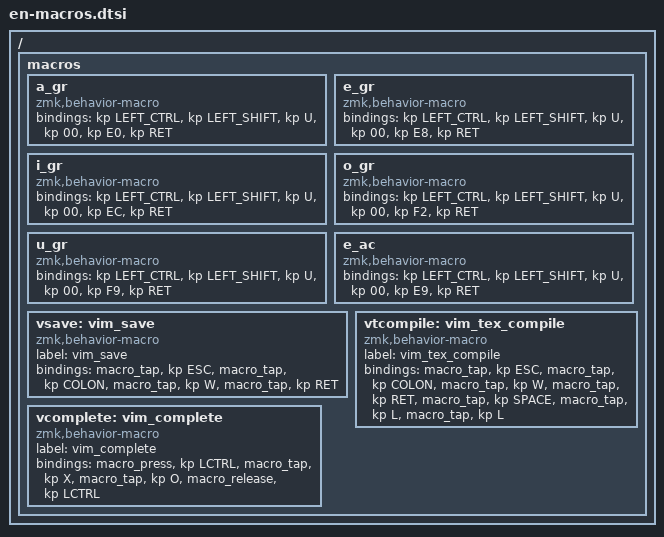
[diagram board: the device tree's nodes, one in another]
/ {

    macros {
        
      // Character à
      a_gr: a_gr {
          compatible = "zmk,behavior-macro";
          #binding-cells = <0>;
          bindings = <&kp LEFT_CTRL>, <&kp LEFT_SHIFT>, <&kp U>, <&kp 00>, <&kp E0>, <&kp RET>;
      };
        
      // Character è
      e_gr: e_gr {
          compatible = "zmk,behavior-macro";
          #binding-cells = <0>;
          bindings = <&kp LEFT_CTRL>, <&kp LEFT_SHIFT>, <&kp U>, <&kp 00>, <&kp E8>, <&kp RET>;
      };
        
      // Character ì
      i_gr: i_gr {
          compatible = "zmk,behavior-macro";
          #binding-cells = <0>;
          bindings = <&kp LEFT_CTRL>, <&kp LEFT_SHIFT>, <&kp U>, <&kp 00>, <&kp EC>, <&kp RET>;
      };
        
      // Character ò
      o_gr: o_gr {
          compatible = "zmk,behavior-macro";
          #binding-cells = <0>;
          bindings = <&kp LEFT_CTRL>, <&kp LEFT_SHIFT>, <&kp U>, <&kp 00>, <&kp F2>, <&kp RET>;
      };
        
      // Character ù
      u_gr: u_gr {
          compatible = "zmk,behavior-macro";
          #binding-cells = <0>;
          bindings = <&kp LEFT_CTRL>, <&kp LEFT_SHIFT>, <&kp U>, <&kp 00>, <&kp F9>, <&kp RET>;
      };

      // Character é 
      e_ac: e_ac {
          compatible = "zmk,behavior-macro";
          #binding-cells = <0>;
          bindings = <&kp LEFT_CTRL>, <&kp LEFT_SHIFT>, <&kp U>, <&kp 00>, <&kp E9>, <&kp RET>;
      };
        
      // Key sequence for saving in vim: Esc :w Enter
      vsave: vim_save {
          label = "vim_save";
          compatible = "zmk,behavior-macro";
          #binding-cells = <0>;
          bindings
              = <&macro_tap &kp ESC>
              , <&macro_tap &kp COLON>
              , <&macro_tap &kp W >
              , <&macro_tap &kp RET >
              ;
      };

      // Key sequence for saving and compilin in vimtex: Esc :w Enter Space l l
      vtcompile: vim_tex_compile {
          label = "vim_tex_compile";
          compatible = "zmk,behavior-macro";
          #binding-cells = <0>;
          bindings
              = <&macro_tap &kp ESC>
              , <&macro_tap &kp COLON>
              , <&macro_tap &kp W>
              , <&macro_tap &kp RET>
              , <&macro_tap &kp SPACE>
              , <&macro_tap &kp L>
              , <&macro_tap &kp L>
              ;
      };
        
      // Key sequence to trigger completion in vim
      vcomplete: vim_complete {
          label = "vim_complete";
          compatible = "zmk,behavior-macro";
          #binding-cells = <0>;
          bindings
              = <&macro_press &kp LCTRL>
              , <&macro_tap &kp X >
              //, <&macro_release &kp LCTRL>
              //, <&macro_press &kp LCTRL>
              , <&macro_tap &kp O >
              , <&macro_release &kp LCTRL>
              ;
      };
        
  };

};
